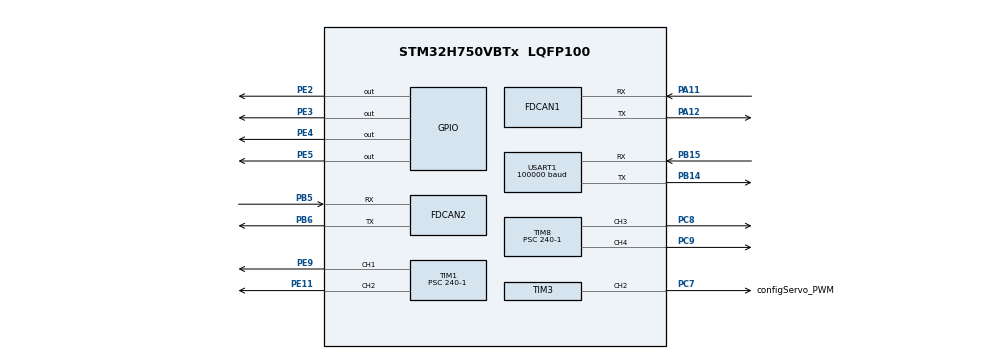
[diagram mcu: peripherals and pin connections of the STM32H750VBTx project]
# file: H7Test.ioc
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Dma.Request0=USART1_RX
Dma.USART1_RX.0.Direction=DMA_PERIPH_TO_MEMORY
Dma.USART1_RX.0.EventEnable=DISABLE
Dma.USART1_RX.0.FIFOMode=DMA_FIFOMODE_DISABLE
Dma.USART1_RX.0.Instance=DMA1_Stream0
Dma.USART1_RX.0.MemDataAlignment=DMA_MDATAALIGN_BYTE
Dma.USART1_RX.0.MemInc=DMA_MINC_ENABLE
Dma.USART1_RX.0.Mode=DMA_CIRCULAR
Dma.USART1_RX.0.PeriphDataAlignment=DMA_PDATAALIGN_BYTE
Dma.USART1_RX.0.PeriphInc=DMA_PINC_DISABLE
Dma.USART1_RX.0.Polarity=HAL_DMAMUX_REQ_GEN_RISING
Dma.USART1_RX.0.Priority=DMA_PRIORITY_VERY_HIGH
Dma.USART1_RX.0.RequestNumber=1
Dma.USART1_RX.0.SignalID=NONE
Dma.USART1_RX.0.SyncEnable=DISABLE
Dma.USART1_RX.0.SyncPolarity=HAL_DMAMUX_SYNC_NO_EVENT
Dma.USART1_RX.0.SyncRequestNumber=1
Dma.USART1_RX.0.SyncSignalID=NONE
FDCAN1.CalculateBaudRateNominal=1000000
FDCAN1.CalculateTimeBitNominal=1000
FDCAN1.CalculateTimeQuantumNominal=25.0
FDCAN1.DataSyncJumpWidth=10
FDCAN1.DataTimeSeg1=29
FDCAN1.DataTimeSeg2=10
FDCAN1.ExtFiltersNbr=1
FDCAN1.FrameFormat=FDCAN_FRAME_FD_BRS
FDCAN1.NominalPrescaler=3
FDCAN1.NominalSyncJumpWidth=8
FDCAN1.NominalTimeSeg1=30
FDCAN1.NominalTimeSeg2=9
FDCAN1.RxFifo0ElmtsNbr=32
FDCAN1.StdFiltersNbr=1
FDCAN1.TxFifoQueueElmtsNbr=32
FDCAN2.CalculateBaudRateNominal=1000000
FDCAN2.CalculateTimeBitNominal=1000
FDCAN2.CalculateTimeQuantumNominal=25.0
FDCAN2.DataSyncJumpWidth=10
FDCAN2.DataTimeSeg1=29
FDCAN2.DataTimeSeg2=10
FDCAN2.ExtFiltersNbr=1
FDCAN2.FrameFormat=FDCAN_FRAME_FD_BRS
FDCAN2.NominalPrescaler=3
FDCAN2.NominalSyncJumpWidth=8
FDCAN2.NominalTimeSeg1=31
FDCAN2.NominalTimeSeg2=8
FDCAN2.RxFifo0ElmtsNbr=32
FDCAN2.StdFiltersNbr=1
FDCAN2.TxFifoQueueElmtsNbr=32
FREERTOS.Tasks01=defaultTask,0,128,StartDefaultTask,Default,NULL,Dynamic,NULL,NULL;Task_Remote,2,200,Remote_Task,As external,NULL,Dynamic,NULL,NULL;Task_Gimbal,2,256,Gimbal_Task,As external,NULL,Dynamic,NULL,NULL;Task_BoardCommu,1,200,BoardCommuni_Task,As external,NULL,Dynamic,NULL,NULL;Task_Detect,-3,128,Detect_Task,As external,NULL,Dynamic,NULL,NULL
FREERTOS.configENABLE_FPU=1
FREERTOS.configUSE_NEWLIB_REENTRANT=0
Mcu.Family=STM32H7
Mcu.Name=STM32H750VBTx
Mcu.Package=LQFP100
NVIC.DMA1_Stream0_IRQn=true\:5\:0\:false\:false\:true\:true\:false\:true\:true
NVIC.FDCAN1_IT0_IRQn=true\:5\:0\:false\:false\:true\:true\:true\:true\:true
NVIC.FDCAN2_IT0_IRQn=true\:5\:0\:false\:false\:true\:true\:true\:true\:true
NVIC.PriorityGroup=NVIC_PRIORITYGROUP_4
NVIC.TIM2_IRQn=true\:15\:0\:false\:false\:true\:false\:false\:true\:true
NVIC.TimeBase=TIM2_IRQn
NVIC.TimeBaseIP=TIM2
NVIC.USART1_IRQn=true\:5\:0\:false\:false\:true\:true\:true\:true\:true
PA11.Mode=FDCAN_Activate
PA11.Signal=FDCAN1_RX
PA12.Mode=FDCAN_Activate
PA12.Signal=FDCAN1_TX
PB14.Mode=Asynchronous
PB14.Signal=USART1_TX
PB15.Mode=Asynchronous
PB15.Signal=USART1_RX
PB5.Mode=FDCAN_Activate
PB5.Signal=FDCAN2_RX
PB6.Mode=FDCAN_Activate
PB6.Signal=FDCAN2_TX
PC7.GPIO_Label=configServo_PWM
PC7.Signal=S_TIM3_CH2
PC8.GPIO_PuPd=GPIO_PULLUP
PC8.Signal=S_TIM8_CH3
PC9.GPIO_PuPd=GPIO_PULLUP
PC9.Signal=S_TIM8_CH4
PE11.GPIO_PuPd=GPIO_PULLUP
PE11.Signal=S_TIM1_CH2
PE2.GPIO_PuPd=GPIO_PULLUP
PE2.Signal=GPIO_Output
PE3.GPIO_PuPd=GPIO_PULLUP
PE3.Signal=GPIO_Output
PE4.GPIO_PuPd=GPIO_PULLUP
PE4.Signal=GPIO_Output
PE5.GPIO_PuPd=GPIO_PULLUP
PE5.Signal=GPIO_Output
PE9.GPIO_PuPd=GPIO_PULLUP
PE9.Signal=S_TIM1_CH1
PH0-OSC_IN\ (PH0).Mode=HSE-External-Oscillator
PH0-OSC_IN\ (PH0).Signal=RCC_OSC_IN
PH1-OSC_OUT\ (PH1).Mode=HSE-External-Oscillator
PH1-OSC_OUT\ (PH1).Signal=RCC_OSC_OUT
ProjectManager.HeapSize=0x200
ProjectManager.StackSize=0x400
ProjectManager.TargetToolchain=STM32CubeIDE
RCC.ADCFreq_Value=240000000
RCC.APB1Freq_Value=120000000
RCC.APB2Freq_Value=120000000
RCC.APB3Freq_Value=120000000
RCC.APB4Freq_Value=120000000
RCC.CortexFreq_Value=480000000
RCC.D1PPRE=RCC_APB3_DIV2
RCC.D2PPRE1=RCC_APB1_DIV2
RCC.D2PPRE2=RCC_APB2_DIV2
RCC.D3PPRE=RCC_APB4_DIV2
RCC.DIVM1=5
RCC.DIVM2=25
RCC.DIVN1=192
RCC.DIVN2=480
RCC.DIVQ1=8
RCC.DIVQ2=4
RCC.HCLKFreq_Value=240000000
RCC.HPRE=RCC_HCLK_DIV2
RCC.PLL2FRACN=0
RCC.PLL3FRACN=0
RCC.PLLFRACN=0
RCC.PLLSourceVirtual=RCC_PLLSOURCE_HSE
RCC.PWR_Regulator_Voltage_Scale=PWR_REGULATOR_VOLTAGE_SCALE0
RCC.ProductRev=revV
RCC.SYSCLKFreq_VALUE=480000000
RCC.SYSCLKSource=RCC_SYSCLKSOURCE_PLLCLK
RCC.USBFreq_Value=120000000
SH.S_TIM1_CH1.0=TIM1_CH1,PWM Generation1 CH1
SH.S_TIM1_CH2.0=TIM1_CH2,PWM Generation2 CH2
SH.S_TIM3_CH2.0=TIM3_CH2,PWM Generation2 CH2
SH.S_TIM8_CH3.0=TIM8_CH3,PWM Generation3 CH3
SH.S_TIM8_CH4.0=TIM8_CH4,PWM Generation4 CH4
STMicroelectronics.X-CUBE-ALGOBUILD.1.3.0.LibraryCcDSPOoLibraryJjDSPOoLibrary=true
TIM1.Channel-PWM\ Generation1\ CH1=TIM_CHANNEL_1
TIM1.Channel-PWM\ Generation2\ CH2=TIM_CHANNEL_2
TIM1.Period=5000-1
TIM1.Prescaler=240-1
TIM3.Channel-PWM\ Generation2\ CH2=TIM_CHANNEL_2
TIM3.Period=19999
TIM3.Prescaler=239
TIM8.Channel-PWM\ Generation3\ CH3=TIM_CHANNEL_3
TIM8.Channel-PWM\ Generation4\ CH4=TIM_CHANNEL_4
TIM8.Period=19999
TIM8.Prescaler=240-1
USART1.BaudRate=100000
USART1.Parity=PARITY_EVEN
USART1.VirtualMode-Asynchronous=VM_ASYNC
USART1.WordLength=WORDLENGTH_9B
VP_FREERTOS_VS_CMSIS_V1.Mode=CMSIS_V1
VP_STMicroelectronics.X-CUBE-ALGOBUILD_VS_DSPOoLibraryJjLibrary_1.3.0_1.3.0.Mode=DSPOoLibraryJjLibrary
VP_SYS_VS_tim2.Mode=TIM2
board=custom

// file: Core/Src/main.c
/* USER CODE BEGIN Header */
/**
  ******************************************************************************
  * @file           : main.c
  * @brief          : Main program body
  ******************************************************************************
  * @attention
  *
  * Copyright (c) 2023 STMicroelectronics.
  * All rights reserved.
  *
  * This software is licensed under terms that can be found in the LICENSE file
  * in the root directory of this software component.
  * If no LICENSE file comes with this software, it is provided AS-IS.
  *
  ******************************************************************************
  */
/* USER CODE END Header */
#include "main.h"
#include "cmsis_os.h"
#include "dma.h"
#include "fdcan.h"
#include "tim.h"
#include "usart.h"
#include "gpio.h"

/* USER CODE BEGIN Includes */
#include "SYSInit.h"

/* USER CODE END Includes */

void SystemClock_Config(void);
void MX_FREERTOS_Init(void);

/* USER CODE BEGIN 0 */
int pwm = 1500;
/* USER CODE END 0 */

int main(void)
{

  /* MCU Configuration--------------------------------------------------------*/

  /* Reset of all peripherals, Initializes the Flash interface and the Systick. */
  HAL_Init();

  /* Configure the system clock */
  SystemClock_Config();

  /* Initialize all configured peripherals */
  MX_GPIO_Init();
  MX_DMA_Init();
  MX_USART1_UART_Init();
  MX_FDCAN1_Init();
  MX_TIM1_Init();
  MX_TIM8_Init();
  MX_TIM3_Init();
  MX_FDCAN2_Init();
  /* USER CODE BEGIN 2 */
	Sys_Init();
		HAL_Delay(20);
  /* USER CODE END 2 */

  /* Call init function for freertos objects (in freertos.c) */
  MX_FREERTOS_Init();

  /* Start scheduler */
  osKernelStart();
  /* We should never get here as control is now taken by the scheduler */
  /* Infinite loop */
  while (1)
  {

    /* USER CODE BEGIN 3 */
		__HAL_TIM_SetCompare(&htim1, TIM_CHANNEL_1, pwm);
		__HAL_TIM_SetCompare(&htim1, TIM_CHANNEL_2, pwm);
		__HAL_TIM_SetCompare(&htim8, TIM_CHANNEL_3, pwm);
		__HAL_TIM_SetCompare(&htim8, TIM_CHANNEL_4, pwm);
		__HAL_TIM_SetCompare(&htim3, TIM_CHANNEL_2, pwm);
		HAL_Delay(20);
  }
  /* USER CODE END 3 */
}

void SystemClock_Config(void)
{
  RCC_OscInitTypeDef RCC_OscInitStruct = {0};
  RCC_ClkInitTypeDef RCC_ClkInitStruct = {0};

  /** Supply configuration update enable
  */
  HAL_PWREx_ConfigSupply(PWR_LDO_SUPPLY);

  /** Configure the main internal regulator output voltage
  */
  __HAL_PWR_VOLTAGESCALING_CONFIG(PWR_REGULATOR_VOLTAGE_SCALE1);

  while(!__HAL_PWR_GET_FLAG(PWR_FLAG_VOSRDY)) {}

  __HAL_RCC_SYSCFG_CLK_ENABLE();
  __HAL_PWR_VOLTAGESCALING_CONFIG(PWR_REGULATOR_VOLTAGE_SCALE0);

  while(!__HAL_PWR_GET_FLAG(PWR_FLAG_VOSRDY)) {}

  /** Initializes the RCC Oscillators according to the specified parameters
  * in the RCC_OscInitTypeDef structure.
  */
  RCC_OscInitStruct.OscillatorType = RCC_OSCILLATORTYPE_HSE;
  RCC_OscInitStruct.HSEState = RCC_HSE_ON;
  RCC_OscInitStruct.PLL.PLLState = RCC_PLL_ON;
  RCC_OscInitStruct.PLL.PLLSource = RCC_PLLSOURCE_HSE;
  RCC_OscInitStruct.PLL.PLLM = 5;
  RCC_OscInitStruct.PLL.PLLN = 192;
  RCC_OscInitStruct.PLL.PLLP = 2;
  RCC_OscInitStruct.PLL.PLLQ = 8;
  RCC_OscInitStruct.PLL.PLLR = 2;
  RCC_OscInitStruct.PLL.PLLRGE = RCC_PLL1VCIRANGE_2;
  RCC_OscInitStruct.PLL.PLLVCOSEL = RCC_PLL1VCOWIDE;
  RCC_OscInitStruct.PLL.PLLFRACN = 0;
  if (HAL_RCC_OscConfig(&RCC_OscInitStruct) != HAL_OK)
  {
    Error_Handler();
  }

  /** Initializes the CPU, AHB and APB buses clocks
  */
  RCC_ClkInitStruct.ClockType = RCC_CLOCKTYPE_HCLK|RCC_CLOCKTYPE_SYSCLK
                              |RCC_CLOCKTYPE_PCLK1|RCC_CLOCKTYPE_PCLK2
                              |RCC_CLOCKTYPE_D3PCLK1|RCC_CLOCKTYPE_D1PCLK1;
  RCC_ClkInitStruct.SYSCLKSource = RCC_SYSCLKSOURCE_PLLCLK;
  RCC_ClkInitStruct.SYSCLKDivider = RCC_SYSCLK_DIV1;
  RCC_ClkInitStruct.AHBCLKDivider = RCC_HCLK_DIV2;
  RCC_ClkInitStruct.APB3CLKDivider = RCC_APB3_DIV2;
  RCC_ClkInitStruct.APB1CLKDivider = RCC_APB1_DIV2;
  RCC_ClkInitStruct.APB2CLKDivider = RCC_APB2_DIV2;
  RCC_ClkInitStruct.APB4CLKDivider = RCC_APB4_DIV2;

  if (HAL_RCC_ClockConfig(&RCC_ClkInitStruct, FLASH_LATENCY_4) != HAL_OK)
  {
    Error_Handler();
  }
}

void HAL_TIM_PeriodElapsedCallback(TIM_HandleTypeDef *htim)
{
  if (htim->Instance == TIM2) {
    HAL_IncTick();
  }
}

void Error_Handler(void)
{
  __disable_irq();
  while (1)
  {
  }
}

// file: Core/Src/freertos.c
/* USER CODE BEGIN Header */
/**
  ******************************************************************************
  * File Name          : freertos.c
  * Description        : Code for freertos applications
  ******************************************************************************
  * @attention
  *
  * Copyright (c) 2023 STMicroelectronics.
  * All rights reserved.
  *
  * This software is licensed under terms that can be found in the LICENSE file
  * in the root directory of this software component.
  * If no LICENSE file comes with this software, it is provided AS-IS.
  *
  ******************************************************************************
  */
/* USER CODE END Header */

#include "FreeRTOS.h"
#include "task.h"
#include "main.h"
#include "cmsis_os.h"

osThreadId defaultTaskHandle;
osThreadId Task_RemoteHandle;
osThreadId Task_GimbalHandle;
osThreadId Task_BoardCommuHandle;
osThreadId Task_DetectHandle;

void StartDefaultTask(void const * argument);
extern void Remote_Task(void const * argument);
extern void Gimbal_Task(void const * argument);
extern void BoardCommuni_Task(void const * argument);
extern void Detect_Task(void const * argument);

void MX_FREERTOS_Init(void); /* (MISRA C 2004 rule 8.1) */

/* GetIdleTaskMemory prototype (linked to static allocation support) */
void vApplicationGetIdleTaskMemory( StaticTask_t **ppxIdleTaskTCBBuffer, StackType_t **ppxIdleTaskStackBuffer, uint32_t *pulIdleTaskStackSize );

/* USER CODE BEGIN GET_IDLE_TASK_MEMORY */
static StaticTask_t xIdleTaskTCBBuffer;
static StackType_t xIdleStack[configMINIMAL_STACK_SIZE];

void vApplicationGetIdleTaskMemory( StaticTask_t **ppxIdleTaskTCBBuffer, StackType_t **ppxIdleTaskStackBuffer, uint32_t *pulIdleTaskStackSize )
{
  *ppxIdleTaskTCBBuffer = &xIdleTaskTCBBuffer;
  *ppxIdleTaskStackBuffer = &xIdleStack[0];
  *pulIdleTaskStackSize = configMINIMAL_STACK_SIZE;
  /* place for user code */
}
/* USER CODE END GET_IDLE_TASK_MEMORY */

void MX_FREERTOS_Init(void) {

  /* Create the thread(s) */
  /* definition and creation of defaultTask */
  osThreadDef(defaultTask, StartDefaultTask, osPriorityNormal, 0, 128);
  defaultTaskHandle = osThreadCreate(osThread(defaultTask), NULL);

  /* definition and creation of Task_Remote */
  osThreadDef(Task_Remote, Remote_Task, osPriorityHigh, 0, 200);
  Task_RemoteHandle = osThreadCreate(osThread(Task_Remote), NULL);

  /* definition and creation of Task_Gimbal */
  osThreadDef(Task_Gimbal, Gimbal_Task, osPriorityHigh, 0, 256);
  Task_GimbalHandle = osThreadCreate(osThread(Task_Gimbal), NULL);

  /* definition and creation of Task_BoardCommu */
  osThreadDef(Task_BoardCommu, BoardCommuni_Task, osPriorityAboveNormal, 0, 200);
  Task_BoardCommuHandle = osThreadCreate(osThread(Task_BoardCommu), NULL);

  /* definition and creation of Task_Detect */
  osThreadDef(Task_Detect, Detect_Task, osPriorityIdle, 0, 128);
  Task_DetectHandle = osThreadCreate(osThread(Task_Detect), NULL);

}

void StartDefaultTask(void const * argument)
{
  for(;;)
  {
    osDelay(1);
  }
}
